# CY8C5888LTI_LP097 register map
File version: 0.1
CY8C58LP
Registers are 8-bit, read-write, no defined reset value unless marked. A register's access mark holds for its fields unless they carry their own. Offsets are from the block's base; lines under a group give offsets from that group; [hi:lo] are bit positions; {n}, {i} and the like mark numbered series; 'fields as' and 'values as' point back to an identical list; <NAME> marks a mode.

## Memory map
0x00000000 ROBOT_ID_REG
0x00000000 UART
0x00000000 PWM_L
0x00000000 PWM_RESET
0x00000000 PWM_R
0x00000000 ENCODER_TMR_RESET
0x00000000 Encoder_R_Timer
0x00000000 Encoder_L_Timer

## ROBOT_ID_REG
Base 0x00000000
0x40006565 ROBOT_ID_REG_STATUS_REG
0x40006585 ROBOT_ID_REG_MASK_REG
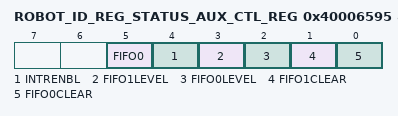
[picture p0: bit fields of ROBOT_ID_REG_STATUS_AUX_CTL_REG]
0x40006595 ROBOT_ID_REG_STATUS_AUX_CTL_REG
  [5] FIFO0 — FIFO0 clear
    1=ENABLED (Enable counter); 0=DISABLED (Disable counter)
  [4] INTRENBL — Enables or disables the Interrupt
    1=ENABLED (Interrupt enabled); 0=DISABLED (Interrupt disabled)
  [3] FIFO1LEVEL — FIFO level
    1=ENABLED (FIFO LVL: input mode: FIFO at least 1/2 empty; output mode: FIFO at least 1/2 full); 0=DISABLED (FIFO LVL: input mode: FIFO not full; output mode: FIFO not empty)
  [2] FIFO0LEVEL — FIFO level
    values as FIFO1LEVEL
  [1] FIFO1CLEAR — FIFO clear
    1=ENABLED (Clear FIFO state); 0=DISABLED (Normal FIFO operation)
  [0] FIFO0CLEAR — FIFO clear
    values as FIFO1CLEAR

## UART
Base 0x00000000
0x40006428 RX_UART_RX_ADDRESS1 — RX Address1 Register
0x40006438 RX_UART_RX_ADDRESS2 — RX Address2 Register
0x40006448 RX_UART_RX_DATA — RX Data Register
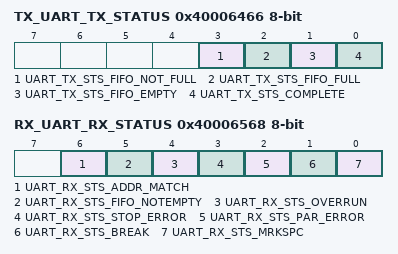
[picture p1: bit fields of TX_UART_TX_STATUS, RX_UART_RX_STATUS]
0x40006466 TX_UART_TX_STATUS — TX status register
  [3] UART_TX_STS_FIFO_NOT_FULL ro, [2] UART_TX_STS_FIFO_FULL ro, [1] UART_TX_STS_FIFO_EMPTY ro, [0] UART_TX_STS_COMPLETE ro
0x40006545 TX_UART_TX_DATA — TX Data Register
0x40006568 RX_UART_RX_STATUS — RX status register
  [6] UART_RX_STS_ADDR_MATCH ro, [5] UART_RX_STS_FIFO_NOTEMPTY ro, [4] UART_RX_STS_OVERRUN ro, [3] UART_RX_STS_STOP_ERROR ro, [2] UART_RX_STS_PAR_ERROR ro, [1] UART_RX_STS_BREAK ro, [0] UART_RX_STS_MRKSPC ro

## PWM_L
Base 0x00000000
0x40006529 PWM_L__COMPARE1 — UDB.D0 - Assigned Compare1 Value
0x40006539 PWM_L__COMPARE2 — UDB.D1 - Assigned Compare2 Value
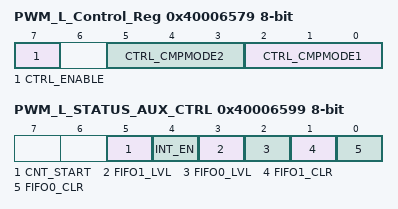
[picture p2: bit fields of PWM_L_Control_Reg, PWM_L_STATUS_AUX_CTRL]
0x40006579 PWM_L_Control_Reg — UDB Control Register - Assigned Control Register Value
  [7] CTRL_ENABLE — Enable the PWM
  [5:3] CTRL_CMPMODE2 — Compare mode 2
  [2:0] CTRL_CMPMODE1 — Compare mode 1
0x40006599 PWM_L_STATUS_AUX_CTRL — UDB Auxilliary Control Register
  [5] CNT_START — FIFO0 clear
    0=E_CNT_START0 (Disable counter); 1=E_CNT_START1 (Enable counter)
  [4] INT_EN
    0=E_INT_EN0 (Interrupt disabled); 1=E_INT_EN1 (Interrupt enabled)
  [3] FIFO1_LVL — FIFO level
    0=E_FIFO_LVL_0 (FIFO LVL: input mode: FIFO not full; output mode: FIFO not empty); 1=E_FIFO_LVL_1 (FIFO LVL: input mode: FIFO at least 1/2 empty; output mode: FIFO at least 1/2 full)
  [2] FIFO0_LVL — FIFO level
    values as FIFO1_LVL
  [1] FIFO1_CLR — FIFO1 clear
    0=E_FIFO_CLR_0 (Normal FIFO operation); 1=E_FIFO_CLR_1 (Clear FIFO state)
  [0] FIFO0_CLR — FIFO0 clear
    values as FIFO1_CLR

## PWM_RESET
Base 0x00000000
0x40006577 PWM_RESET_CONTROL_REG

## PWM_R
Base 0x00000000
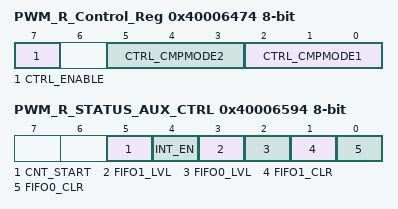
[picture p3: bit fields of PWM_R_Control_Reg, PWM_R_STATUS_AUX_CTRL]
0x40006474 PWM_R_Control_Reg — UDB Control Register - Assigned Control Register Value
  [7] CTRL_ENABLE — Enable the PWM
  [5:3] CTRL_CMPMODE2 — Compare mode 2
  [2:0] CTRL_CMPMODE1 — Compare mode 1
0x40006524 PWM_R__COMPARE1 — UDB.D0 - Assigned Compare1 Value
0x40006534 PWM_R__COMPARE2 — UDB.D1 - Assigned Compare2 Value
0x40006594 PWM_R_STATUS_AUX_CTRL — UDB Auxilliary Control Register
  fields as PWM_L.PWM_L_STATUS_AUX_CTRL

## ENCODER_TMR_RESET
Base 0x00000000
0x40006576 ENCODER_TMR_RESET_CONTROL_REG

## Encoder_R_Timer
Base 0x00000000
0x40006404 Encoder_R_Timer_COUNTER 16-bit — UDB.A0 - Current Down Counter Value
0x40006424 Encoder_R_Timer_PERIOD 16-bit — UDB.D0 - Assigned Period
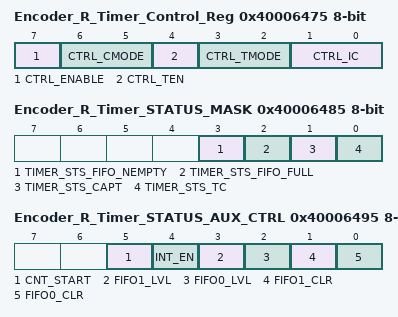
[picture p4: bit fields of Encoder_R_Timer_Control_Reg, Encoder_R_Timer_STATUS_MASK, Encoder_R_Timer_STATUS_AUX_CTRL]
0x40006475 Encoder_R_Timer_Control_Reg — UDB Control Register - Assigned Control Register Value
  [7] CTRL_ENABLE — Enable the Timer
  [6:5] CTRL_CMODE — Capture Mode
  [4] CTRL_TEN — Trigger Enable Bit
  [3:2] CTRL_TMODE — Trigger Mode
  [1:0] CTRL_IC — Interrupt Count
0x40006485 Encoder_R_Timer_STATUS_MASK — UDB Status bits Interrupt Mask Enable Register
  [3] TIMER_STS_FIFO_NEMPTY ro — FIFO Empty status
  [2] TIMER_STS_FIFO_FULL ro — FIFO Full Status
  [1] TIMER_STS_CAPT ro — Enables the Interrupt on Capture
  [0] TIMER_STS_TC ro — Enables the Interrupt on TC
0x40006495 Encoder_R_Timer_STATUS_AUX_CTRL — UDB Auxilliary Control Register
  fields as PWM_L.PWM_L_STATUS_AUX_CTRL

## Encoder_L_Timer
Base 0x00000000
0x40006406 Encoder_L_Timer_COUNTER 16-bit — UDB.A0 - Current Down Counter Value
0x40006426 Encoder_L_Timer_PERIOD 16-bit — UDB.D0 - Assigned Period
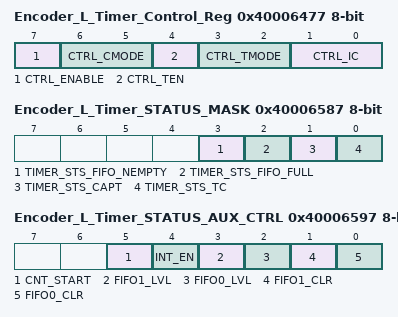
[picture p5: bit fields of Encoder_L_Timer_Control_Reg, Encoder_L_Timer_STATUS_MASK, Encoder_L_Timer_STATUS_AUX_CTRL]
0x40006477 Encoder_L_Timer_Control_Reg — UDB Control Register - Assigned Control Register Value
  [7] CTRL_ENABLE — Enable the Timer
  [6:5] CTRL_CMODE — Capture Mode
  [4] CTRL_TEN — Trigger Enable Bit
  [3:2] CTRL_TMODE — Trigger Mode
  [1:0] CTRL_IC — Interrupt Count
0x40006587 Encoder_L_Timer_STATUS_MASK — UDB Status bits Interrupt Mask Enable Register
  fields as Encoder_R_Timer.Encoder_R_Timer_STATUS_MASK
0x40006597 Encoder_L_Timer_STATUS_AUX_CTRL — UDB Auxilliary Control Register
  fields as PWM_L.PWM_L_STATUS_AUX_CTRL
